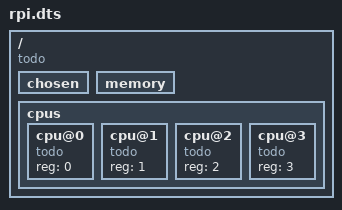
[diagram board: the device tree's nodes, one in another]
/dts-v1/;

/ {
  compatible = "todo";
  chosen {
  };
  memory {
  };
  cpus {
    #address-cells = <1>;
    #size-cells = <0>;
    cpu@0 {
      compatible = "todo";
      reg = <0>;
    };
    cpu@1 {
      compatible = "todo";
      reg = <1>;
    };
    cpu@2 {
      compatible = "todo";
      reg = <2>;
    };
    cpu@3 {
      compatible = "todo";
      reg = <3>;
    };
  };
};
